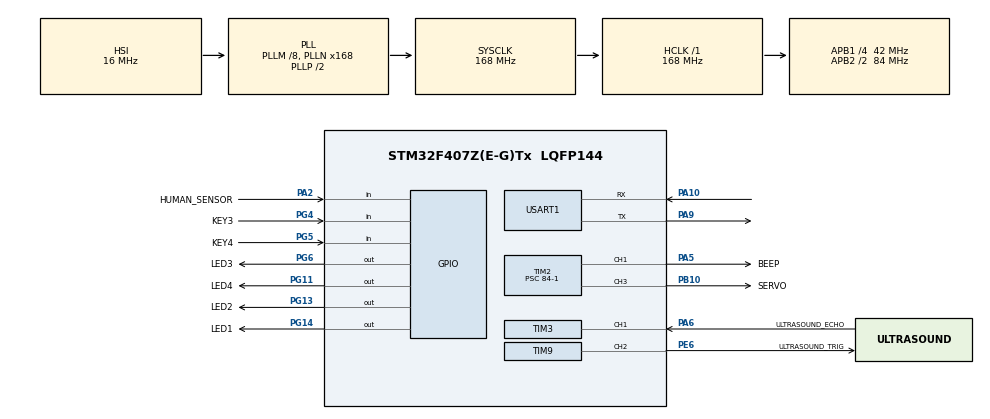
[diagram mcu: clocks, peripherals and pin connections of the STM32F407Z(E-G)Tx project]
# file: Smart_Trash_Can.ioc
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FREERTOS.INCLUDE_vTaskDelayUntil=1
FREERTOS.Tasks01=defaultTask,0,128,StartDefaultTask,Default,NULL,Dynamic,NULL,NULL
Mcu.Family=STM32F4
Mcu.Name=STM32F407Z(E-G)Tx
Mcu.Package=LQFP144
NVIC.PriorityGroup=NVIC_PRIORITYGROUP_4
NVIC.TIM3_IRQn=true\:5\:0\:false\:false\:true\:true\:true\:true\:true
NVIC.USART1_IRQn=true\:5\:0\:false\:false\:true\:true\:true\:true\:true
PA10.Mode=Asynchronous
PA10.Signal=USART1_RX
PA13.Mode=Serial_Wire
PA13.Signal=SYS_JTMS-SWDIO
PA14.Mode=Serial_Wire
PA14.Signal=SYS_JTCK-SWCLK
PA2.GPIO_Label=HUMAN_SENSOR
PA2.GPIO_PuPd=GPIO_PULLDOWN
PA2.Signal=GPIO_Input
PA5.GPIO_Label=BEEP
PA5.Signal=S_TIM2_CH1_ETR
PA6.GPIO_Label=ULTRASOUND_ECHO
PA6.GPIO_PuPd=GPIO_PULLDOWN
PA6.Signal=S_TIM3_CH1
PA9.Mode=Asynchronous
PA9.Signal=USART1_TX
PB10.GPIO_Label=SERVO
PB10.Signal=S_TIM2_CH3
PE6.GPIO_Label=ULTRASOUND_TRIG
PE6.Signal=S_TIM9_CH2
PG11.GPIO_Label=LED4
PG11.PinState=GPIO_PIN_SET
PG11.Signal=GPIO_Output
PG13.GPIO_Label=LED2
PG13.PinState=GPIO_PIN_SET
PG13.Signal=GPIO_Output
PG14.GPIO_Label=LED1
PG14.PinState=GPIO_PIN_SET
PG14.Signal=GPIO_Output
PG4.GPIO_Label=KEY3
PG4.Signal=GPIO_Input
PG5.GPIO_Label=KEY4
PG5.Signal=GPIO_Input
PG6.GPIO_Label=LED3
PG6.PinState=GPIO_PIN_SET
PG6.Signal=GPIO_Output
PH0-OSC_IN.Mode=HSE-External-Oscillator
PH0-OSC_IN.Signal=RCC_OSC_IN
PH1-OSC_OUT.Mode=HSE-External-Oscillator
PH1-OSC_OUT.Signal=RCC_OSC_OUT
ProjectManager.HeapSize=0x200
ProjectManager.StackSize=0x400
ProjectManager.TargetToolchain=MDK-ARM V5.32
RCC.48MHZClocksFreq_Value=84000000
RCC.AHBFreq_Value=168000000
RCC.APB1CLKDivider=RCC_HCLK_DIV4
RCC.APB1Freq_Value=42000000
RCC.APB1TimFreq_Value=84000000
RCC.APB2CLKDivider=RCC_HCLK_DIV2
RCC.APB2Freq_Value=84000000
RCC.APB2TimFreq_Value=168000000
RCC.CortexFreq_Value=168000000
RCC.HCLKFreq_Value=168000000
RCC.HSE_VALUE=25000000
RCC.HSI_VALUE=16000000
RCC.LSE_VALUE=32768
RCC.PLLM=8
RCC.PLLN=168
RCC.SYSCLKFreq_VALUE=168000000
RCC.SYSCLKSource=RCC_SYSCLKSOURCE_PLLCLK
RCC.VCOOutputFreq_Value=336000000
SH.S_TIM2_CH1_ETR.0=TIM2_CH1,PWM Generation1 CH1
SH.S_TIM2_CH3.0=TIM2_CH3,PWM Generation3 CH3
SH.S_TIM3_CH1.0=TIM3_CH1,Input_Capture1_from_TI1
SH.S_TIM9_CH2.0=TIM9_CH2,PWM Generation2 CH2
TIM2.Channel-PWM\ Generation1\ CH1=TIM_CHANNEL_1
TIM2.Channel-PWM\ Generation3\ CH3=TIM_CHANNEL_3
TIM2.Period=20000-1
TIM2.Prescaler=84-1
TIM3.AutoReloadPreload=TIM_AUTORELOAD_PRELOAD_ENABLE
TIM3.Channel-Input_Capture1_from_TI1=TIM_CHANNEL_1
TIM3.Prescaler=8400-1
TIM9.Channel-PWM\ Generation2\ CH2=TIM_CHANNEL_2
TIM9.Period=50000-1
TIM9.Prescaler=168-1
TIM9.Pulse-PWM\ Generation2\ CH2=500
USART1.VirtualMode=VM_ASYNC
VP_FREERTOS_VS_CMSIS_V1.Mode=CMSIS_V1
board=custom

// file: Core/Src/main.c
/* USER CODE BEGIN Header */
/**
  ******************************************************************************
  * @file           : main.c
  * @brief          : Main program body
  ******************************************************************************
  * @attention
  *
  * Copyright (c) 2025 STMicroelectronics.
  * All rights reserved.
  *
  * This software is licensed under terms that can be found in the LICENSE file
  * in the root directory of this software component.
  * If no LICENSE file comes with this software, it is provided AS-IS.
  *
  ******************************************************************************
  */
/* USER CODE END Header */
#include "main.h"
#include "cmsis_os.h"
#include "tim.h"
#include "usart.h"
#include "gpio.h"

/* USER CODE BEGIN Includes */
#include "led_task.h"
/* USER CODE END Includes */

void SystemClock_Config(void);
void MX_FREERTOS_Init(void);

int main(void)
{

  /* MCU Configuration--------------------------------------------------------*/

  /* Reset of all peripherals, Initializes the Flash interface and the Systick. */
  HAL_Init();

  /* Configure the system clock */
  SystemClock_Config();

  /* Initialize all configured peripherals */
  MX_GPIO_Init();
  MX_TIM2_Init();
  MX_TIM3_Init();
  MX_TIM9_Init();
  MX_USART1_UART_Init();

  /* Call init function for freertos objects (in freertos.c) */
  MX_FREERTOS_Init();

  /* Start scheduler */
  osKernelStart();

  /* We should never get here as control is now taken by the scheduler */
  /* Infinite loop */
  while (1)
  {

  }
}

void SystemClock_Config(void)
{
  RCC_OscInitTypeDef RCC_OscInitStruct = {0};
  RCC_ClkInitTypeDef RCC_ClkInitStruct = {0};

  /** Configure the main internal regulator output voltage
  */
  __HAL_RCC_PWR_CLK_ENABLE();
  __HAL_PWR_VOLTAGESCALING_CONFIG(PWR_REGULATOR_VOLTAGE_SCALE1);

  /** Initializes the RCC Oscillators according to the specified parameters
  * in the RCC_OscInitTypeDef structure.
  */
  RCC_OscInitStruct.OscillatorType = RCC_OSCILLATORTYPE_HSI;
  RCC_OscInitStruct.HSIState = RCC_HSI_ON;
  RCC_OscInitStruct.HSICalibrationValue = RCC_HSICALIBRATION_DEFAULT;
  RCC_OscInitStruct.PLL.PLLState = RCC_PLL_ON;
  RCC_OscInitStruct.PLL.PLLSource = RCC_PLLSOURCE_HSI;
  RCC_OscInitStruct.PLL.PLLM = 8;
  RCC_OscInitStruct.PLL.PLLN = 168;
  RCC_OscInitStruct.PLL.PLLP = RCC_PLLP_DIV2;
  RCC_OscInitStruct.PLL.PLLQ = 4;
  if (HAL_RCC_OscConfig(&RCC_OscInitStruct) != HAL_OK)
  {
    Error_Handler();
  }

  /** Initializes the CPU, AHB and APB buses clocks
  */
  RCC_ClkInitStruct.ClockType = RCC_CLOCKTYPE_HCLK|RCC_CLOCKTYPE_SYSCLK
                              |RCC_CLOCKTYPE_PCLK1|RCC_CLOCKTYPE_PCLK2;
  RCC_ClkInitStruct.SYSCLKSource = RCC_SYSCLKSOURCE_PLLCLK;
  RCC_ClkInitStruct.AHBCLKDivider = RCC_SYSCLK_DIV1;
  RCC_ClkInitStruct.APB1CLKDivider = RCC_HCLK_DIV4;
  RCC_ClkInitStruct.APB2CLKDivider = RCC_HCLK_DIV2;

  if (HAL_RCC_ClockConfig(&RCC_ClkInitStruct, FLASH_LATENCY_5) != HAL_OK)
  {
    Error_Handler();
  }
}

void Error_Handler(void)
{
  __disable_irq();
  while (1)
  {
  }
}

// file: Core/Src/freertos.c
/* USER CODE BEGIN Header */
/**
  ******************************************************************************
  * File Name          : freertos.c
  * Description        : Code for freertos applications
  ******************************************************************************
  * @attention
  *
  * Copyright (c) 2025 STMicroelectronics.
  * All rights reserved.
  *
  * This software is licensed under terms that can be found in the LICENSE file
  * in the root directory of this software component.
  * If no LICENSE file comes with this software, it is provided AS-IS.
  *
  ******************************************************************************
  */
/* USER CODE END Header */

#include "FreeRTOS.h"
#include "task.h"
#include "main.h"
#include "cmsis_os.h"

/* USER CODE BEGIN Includes */
#include "trash_can_task.h"
#include "led_task.h"
#include "echo.h"
/* USER CODE END Includes */

/* USER CODE BEGIN Variables */
osThreadId trashCanTaskHandle;
osThreadId ledTaskHandle;
osThreadId echoTaskHandle;
/* USER CODE END Variables */
osThreadId defaultTaskHandle;

void StartDefaultTask(void const * argument);

void MX_FREERTOS_Init(void); /* (MISRA C 2004 rule 8.1) */

/* GetIdleTaskMemory prototype (linked to static allocation support) */
void vApplicationGetIdleTaskMemory( StaticTask_t **ppxIdleTaskTCBBuffer, StackType_t **ppxIdleTaskStackBuffer, uint32_t *pulIdleTaskStackSize );

/* USER CODE BEGIN GET_IDLE_TASK_MEMORY */
static StaticTask_t xIdleTaskTCBBuffer;
static StackType_t xIdleStack[configMINIMAL_STACK_SIZE];

void vApplicationGetIdleTaskMemory( StaticTask_t **ppxIdleTaskTCBBuffer, StackType_t **ppxIdleTaskStackBuffer, uint32_t *pulIdleTaskStackSize )
{
  *ppxIdleTaskTCBBuffer = &xIdleTaskTCBBuffer;
  *ppxIdleTaskStackBuffer = &xIdleStack[0];
  *pulIdleTaskStackSize = configMINIMAL_STACK_SIZE;
  /* place for user code */
}
/* USER CODE END GET_IDLE_TASK_MEMORY */

void MX_FREERTOS_Init(void) {

  /* Create the thread(s) */
  /* definition and creation of defaultTask */
  osThreadDef(defaultTask, StartDefaultTask, osPriorityNormal, 0, 128);
  defaultTaskHandle = osThreadCreate(osThread(defaultTask), NULL);

  /* USER CODE BEGIN RTOS_THREADS */
  osThreadDef(trashCanTask, trash_can_task, osPriorityNormal, 0, 128);
  trashCanTaskHandle = osThreadCreate(osThread(trashCanTask), NULL);

  osThreadDef(ledTask, led_task, osPriorityNormal, 0, 128);
  ledTaskHandle = osThreadCreate(osThread(ledTask), NULL);

  osThreadDef(echoTask, echo_task, osPriorityNormal, 0, 128);
  echoTaskHandle = osThreadCreate(osThread(echoTask), NULL);
  /* USER CODE END RTOS_THREADS */

}

void StartDefaultTask(void const * argument)
{
  for(;;)
  {
    osDelay(1);
  }
}
